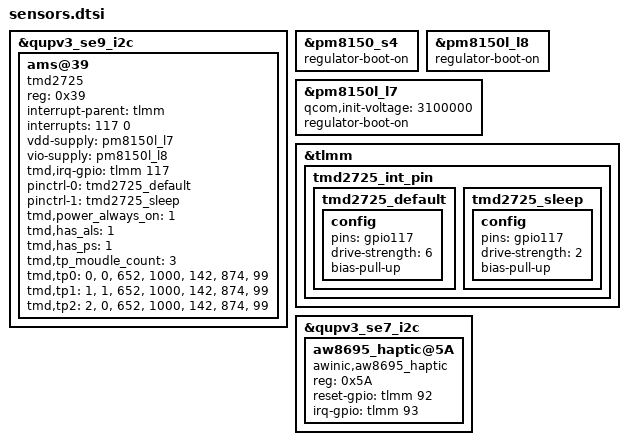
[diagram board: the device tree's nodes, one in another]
/*
 * Copyright (c) 2015-2018, The Linux Foundation. All rights reserved.
 *
 * This program is free software; you can redistribute it and/or modify
 * it under the terms of the GNU General Public License version 2 and
 * only version 2 as published by the Free Software Foundation.
 *
 * This program is distributed in the hope that it will be useful,
 * but WITHOUT ANY WARRANTY; without even the implied warranty of
 * MERCHANTABILITY or FITNESS FOR A PARTICULAR PURPOSE.  See the
 * GNU General Public License for more details.
 */

&qupv3_se9_i2c {
	/delete-node/ nubia@39;
};

&qupv3_se9_i2c {
	status = "ok";
	ams@39 {
		compatible = "tmd2725";
		reg = <0x39>;
		interrupt-parent = <&tlmm>;
		interrupts = <117 0>;
		vdd-supply = <&pm8150l_l7>;
		//vio-supply = <&pm8998_s4>;
		vio-supply = <&pm8150l_l8>;
		tmd,irq-gpio = <&tlmm 117 0x00>;
		pinctrl-names = "tmd2725_default","tmd2725_sleep";
		pinctrl-0 = <&tmd2725_default>;
		pinctrl-1 = <&tmd2725_sleep>;
		tmd,power_always_on = <1>;
		tmd,has_als = <1>;
		tmd,has_ps = <1>;
		tmd,tp_moudle_count = <3>;
		//[module_id] [which_seg] [d_factor] ch0[1] ch1[0] ch0[1] ch1[0]
		tmd,tp0 = "0","0","652","1000","142","874","99";
		//[module_id] [which_seg] [d_factor] ch0[1] ch1[0] ch0[1] ch1[0]
		tmd,tp1 = "1","1","652","1000","142","874","99";
		//[module_id] [which_seg] [d_factor] ch0[1] ch1[0] ch0[1] ch1[0]
		tmd,tp2 = "2","0","652","1000","142","874","99";
	};
};

&pm8150_s4 {
	status = "ok";
	regulator-boot-on;
};

&pm8150l_l8 {
	status = "ok";
	regulator-boot-on;
};

&pm8150l_l7 {
	status = "ok";
	qcom,init-voltage = <3100000>;
	regulator-boot-on;
};

&tlmm {
	tmd2725_int_pin {
		tmd2725_default: tmd2725_default {
			config {
				pins = "gpio117";
				drive-strength = <6>;
				bias-pull-up;
			};
		};
		tmd2725_sleep: tmd2725_sleep {
			config {
				pins = "gpio117";
				drive-strength = <2>;
				bias-pull-up;
			};
		};
	};
};



/* AWINIC AW8695 Haptic */
&qupv3_se7_i2c {
aw8695_haptic@5A {
compatible = "awinic,aw8695_haptic";
reg = <0x5A>;
reset-gpio = <&tlmm 92 0>;
irq-gpio = <&tlmm 93 0>;
status = "okay";
};
};
/* AWINIC AW8695 Haptic End */
